# DECODER0_PVDEC_VEC_BE_HEVC register map
Vendor: Texas Instruments
Peripheral module from a debugger description file (folder J7ES).
Registers are 32-bit, read-write, reset 0x0 unless marked. A register's access mark holds for its fields unless they carry their own. Offsets are as the file gives them; lines under a group give offsets from that group; [hi:lo] are bit positions; {n}, {i} and the like mark numbered series; 'fields as' and 'values as' point back to an identical list; <NAME> marks a mode.

## DECODER0_PVDEC_VEC_BE_HEVC
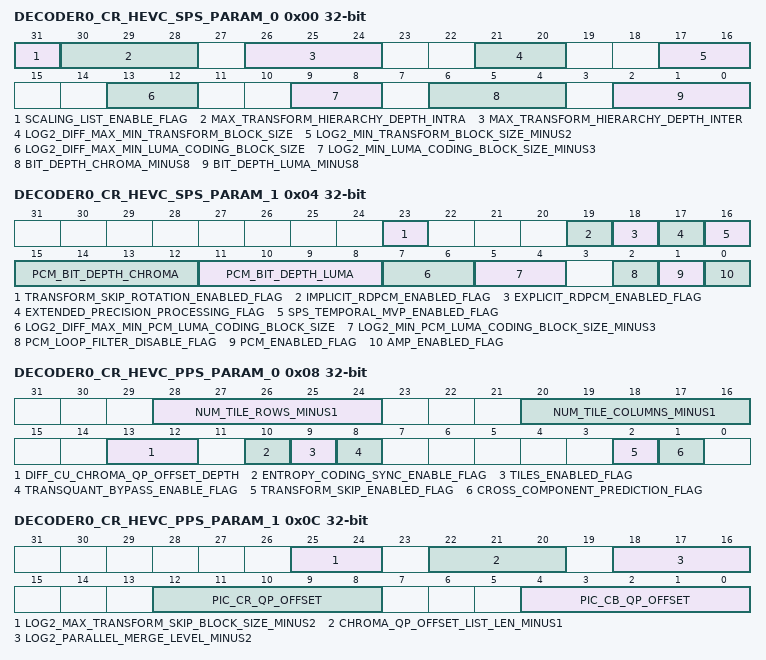
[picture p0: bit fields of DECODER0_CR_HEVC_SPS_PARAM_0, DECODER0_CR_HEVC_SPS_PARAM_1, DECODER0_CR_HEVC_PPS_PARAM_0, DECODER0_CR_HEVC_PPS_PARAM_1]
0x00 DECODER0_CR_HEVC_SPS_PARAM_0
  [31] SCALING_LIST_ENABLE_FLAG — When set to 1, the parameters set in PVDEC IQ RAM define the scaling parameters [software should program default scaling factors if explict values aren't defined in the bit stream].
  [30:28] MAX_TRANSFORM_HIERARCHY_DEPTH_INTRA — Defines the maximum hierarchy depth an Intra Coded block can be split into smaller transforms [cannot be gretaer than Log2CtbSizeY [maximum is
  [26:24] MAX_TRANSFORM_HIERARCHY_DEPTH_INTER — Defines the maximum hierarchy depth an Inter Coded block can be split into smaller transforms [cannot be gretaer than Log2CtbSizeY [maximum is
  [21:20] LOG2_DIFF_MAX_MIN_TRANSFORM_BLOCK_SIZE — Defines the difference between minimum and maximum transform block size [where LOG2_MIN_TRANSFORM_BLOCK_SIZE_MINUS2 + LOG2_DIFF_MAX_MIN_TRANSFORM_BLOCK_SIZE must be &lt;= 3, and must also be less than or equal to the maximum coded block size]
  [17:16] LOG2_MIN_TRANSFORM_BLOCK_SIZE_MINUS2 — Defines the minimum transform block size [where the minimum transform block size can not be greater than the minimum luma coded block size]
  [13:12] LOG2_DIFF_MAX_MIN_LUMA_CODING_BLOCK_SIZE — Defines the difference between minimum and maximum luma coded block size, where the resulting size is sometimes refered to as the Coded Tree Unit size or CTU_SIZE [where for Main Profile, LOG2_MIN_LUMA_CODING_BLOCK_SIZE_MINUS3 + LOG2_DIFF_MAX_MIN_LUMA_CODING_BLOCK_SIZE will be in the range 1 to 3]
  [9:8] LOG2_MIN_LUMA_CODING_BLOCK_SIZE_MINUS3 — Defines the minimum luma coded block size
  [6:4] BIT_DEPTH_CHROMA_MINUS8 — 8 less than the bit depth of chroma samples
  [2:0] BIT_DEPTH_LUMA_MINUS8 — 8 less than the bit depth of luma samples
0x04 DECODER0_CR_HEVC_SPS_PARAM_1
  [23] TRANSFORM_SKIP_ROTATION_ENABLED_FLAG — Indicates that the residual coefficients for a 4x4 Intra transform skip block should be rotated 180 degrees
  [19] IMPLICIT_RDPCM_ENABLED_FLAG — Indicates that the residual modification process for blocks using a transform bypass may be used for intra blocks
  [18] EXPLICIT_RDPCM_ENABLED_FLAG — Indicates that the residual modification process for blocks using a transform bypass may be used for inter blocks
  [17] EXTENDED_PRECISION_PROCESSING_FLAG — Indicates that an extended dynamic range is used for inter prediction interpolation and inverse transform processing
  [16] SPS_TEMPORAL_MVP_ENABLED_FLAG — If this field is set, temporal motion vector prediction may be used, so on P and B slices temporal motion vector parameters should be output in case they are required in future frames.
  [15:12] PCM_BIT_DEPTH_CHROMA — This field is 1 greater than the 'psm_sample_bit_depth_chroma_minus1' field in the bitstream, where this field can be in the range 1 to 14, but must be less than or equal to chroma sample depth
  [11:8] PCM_BIT_DEPTH_LUMA — This field is 1 greater than the 'psm_sample_bit_depth_luma_minus1' field in the bitstream, where this field can be in the range 1 to 14, but must be less than or equal to luma sample depth
  [7:6] LOG2_DIFF_MAX_MIN_PCM_LUMA_CODING_BLOCK_SIZE — If PCM is enabled, defines the difference between minimum and maximum coded block size at which PCM coding may be used [where LOG2_MIN_PCM_LUMA_CODING_BLOCK_SIZE_MINUS3 + LOG2_DIFF_MAX_MIN_PCM_LUMA_CODING_BLOCK_SIZE must be &lt;= 2]
  [5:4] LOG2_MIN_PCM_LUMA_CODING_BLOCK_SIZE_MINUS3 — If PCM is enabled, defines the minimum coded block size at which PCM coding may be used
  [2] PCM_LOOP_FILTER_DISABLE_FLAG — If PCM is enabled, this flag controls if in-loop filtering is disabled for PCM samples
  [1] PCM_ENABLED_FLAG — When set it indicates PCM coded blocks may be included in the bitstream
  [0] AMP_ENABLED_FLAG — When set it indicates PartMode of Inter prediction blocks can use asymmetric motion partitions
0x08 DECODER0_CR_HEVC_PPS_PARAM_0
  [28:24] NUM_TILE_ROWS_MINUS1 — If tiles are enabled, this field is one less than the number of tile rows the picture has been split into [where a value of zero means a tile spans the whole picture height]
  [20:16] NUM_TILE_COLUMNS_MINUS1 — If tiles are enabled, this field is one less than the number of tile columns the picture has been split into [where a value of zero means a tile spans the whole picture width]
  [13:12] DIFF_CU_CHROMA_QP_OFFSET_DEPTH — Indicates the difference between the luma coding tree block size and the minimum luma coding block size of coding units that convey cu_chroma_qp_offset_flag and cu_chroma_qp_offset_idx
  [10] ENTROPY_CODING_SYNC_ENABLE_FLAG — When set indicates CABAC state is stored after 2 CTUs in a tile row, which is then used to initialise the CABAC at the start of the next tile row
  [9] TILES_ENABLED_FLAG — When set indicates the picture is divided into tiles
  [8] TRANSQUANT_BYPASS_ENABLE_FLAG — When set indicates the cu_transquant_bypass_flag is present in the coded unit
  [2] TRANSFORM_SKIP_ENABLED_FLAG — When set indicates transform_skip_flag may be present in the residual coding syntax
  [1] CROSS_COMPONENT_PREDICTION_FLAG — Indicates that log2_res_scale_abs_plus1 and res_scale_sign_flag may be present in the transform unit syntax
0x0C DECODER0_CR_HEVC_PPS_PARAM_1
  [25:24] LOG2_MAX_TRANSFORM_SKIP_BLOCK_SIZE_MINUS2 — Indicates the maximum transform block size for which transform_skip_flag may be present [will not be larger than the largest transform block size]
  [22:20] CHROMA_QP_OFFSET_LIST_LEN_MINUS1 — Specifies 1 less than the number of cb_qp_offset_list and cr_qp_offset_list syntax elements that are present
  [18:16] LOG2_PARALLEL_MERGE_LEVEL_MINUS2 — Specifies the level at which merge/skip mode uses a single merge candidate.
  [12:8] PIC_CR_QP_OFFSET — Signed offset for QPCr relative to QPy in the range -12 to +12
  [4:0] PIC_CB_QP_OFFSET — Signed offset for QPCb relative to QPy in the range -12 to +12
0x10 DECODER0_CR_HEVC_CB_QP_OFFSET_LIST
  [29:25] PPS_CB_QP_OFFSET_LIST — List of up-to 6 sets of signed offsets for QPCb relative to QPy in the range -12 to +12 [If chroma_qp_offset_list_enabled_flag is 0, these fields should be set to 0]
0x14 DECODER0_CR_HEVC_CR_QP_OFFSET_LIST
  [29:25] PPS_CR_QP_OFFSET_LIST — List of up-to 6 sets of signed offsets for QPCr relative to QPy in the range -12 to +12 [If chroma_qp_offset_list_enabled_flag is 0, these fields should be set to 0]
0x30 DECODER0_CR_HEVC_TEMPORAL_IN_BASE_ADDRESS
  [31:6] TEMPORAL_PARAM_IN_BASE_ADDRESS — The base address of a host memory buffer which contains colocated prediction type and motion vector parameters.
0x34 DECODER0_CR_HEVC_TEMPORAL_OUT_BASE_ADDRESS
  [31:6] TEMPORAL_PARAM_OUT_BASE_ADDRESS — The base address of a host memory buffer to which prediction type and motion vector parameters are written if SPS_TEMPORAL_MVP_ENABLED_FLAG is set
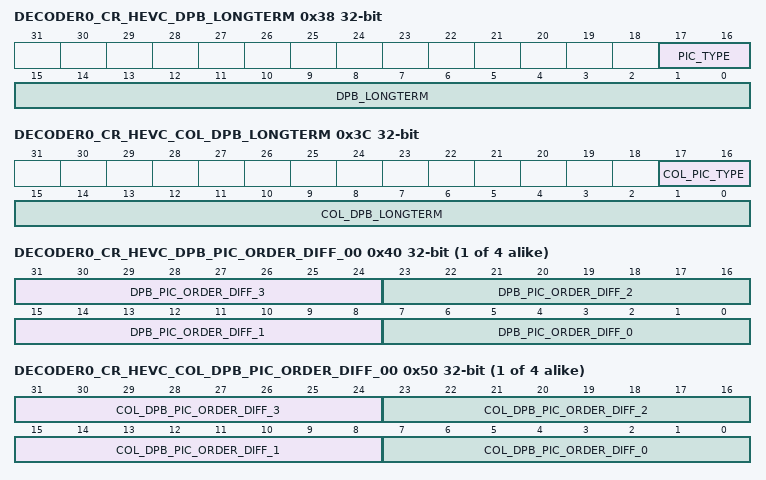
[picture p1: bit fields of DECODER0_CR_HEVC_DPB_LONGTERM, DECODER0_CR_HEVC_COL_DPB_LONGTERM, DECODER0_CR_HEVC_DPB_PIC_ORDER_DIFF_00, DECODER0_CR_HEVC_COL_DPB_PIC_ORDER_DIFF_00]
0x38 DECODER0_CR_HEVC_DPB_LONGTERM
  [17:16] PIC_TYPE — This field is from an access unit delimiter [if present].
  [15:0] DPB_LONGTERM
0x3C DECODER0_CR_HEVC_COL_DPB_LONGTERM
  [17:16] COL_PIC_TYPE — This field must be set to the same value that PIC_TYPE was set to when the collocated picture was being decoded [and must be set before the Pixel pipe decoding of a picture can start].
  [15:0] COL_DPB_LONGTERM — Essentially the same as the 'DPB_LONGTERM' field which was used when the collocated picture was the current picture,
{0x40+4i} DECODER0_CR_HEVC_DPB_PIC_ORDER_DIFF_{i:02} (i=0..3)
  [31:24] DPB_PIC_ORDER_DIFF_3 — The result of PicOrderCntVal - PicOrderCnt[DPB_Index], clipped to the range -128 to 127 [for DPB_index n*4+3] [equivalent to td or tb calculation in equation
  [23:16] DPB_PIC_ORDER_DIFF_2 — The result of PicOrderCntVal - PicOrderCnt[DPB_Index], clipped to the range -128 to 127 [for DPB_index n*4+2] [equivalent to td or tb calculation in equation
  [15:8] DPB_PIC_ORDER_DIFF_1 — The result of PicOrderCntVal - PicOrderCnt[DPB_Index], clipped to the range -128 to 127 [for DPB_index n*4+1] [equivalent to td or tb calculation in equation
  [7:0] DPB_PIC_ORDER_DIFF_0 — The result of PicOrderCntVal - PicOrderCnt[DPB_Index], clipped to the range -128 to 127 [for DPB_index n*4+0] [equivalent to td or tb calculation in equation
{0x50+4i} DECODER0_CR_HEVC_COL_DPB_PIC_ORDER_DIFF_{i:02} (i=0..3)
  [31:24] COL_DPB_PIC_ORDER_DIFF_3 — The result of PicOrderCnt[colPic] - RefPicOrderCnt[colPic, DPB_Index], clipped to the range -128 to 127 [for DPB_index n*4+3] [equivalent to td calculation in equation
  [23:16] COL_DPB_PIC_ORDER_DIFF_2 — The result of PicOrderCnt[colPic] - RefPicOrderCnt[colPic, DPB_Index], clipped to the range -128 to 127 [for DPB_index n*4+2] [equivalent to td calculation in equation
  [15:8] COL_DPB_PIC_ORDER_DIFF_1 — The result of PicOrderCnt[colPic] - RefPicOrderCnt[colPic, DPB_Index], clipped to the range -128 to 127 [for DPB_index n*4+1] [equivalent to td calculation in equation
  [7:0] COL_DPB_PIC_ORDER_DIFF_0 — The result of PicOrderCnt[colPic] - RefPicOrderCnt[colPic, DPB_Index], clipped to the range -128 to 127 [for DPB_index n*4+0] [equivalent to td calculation in equation
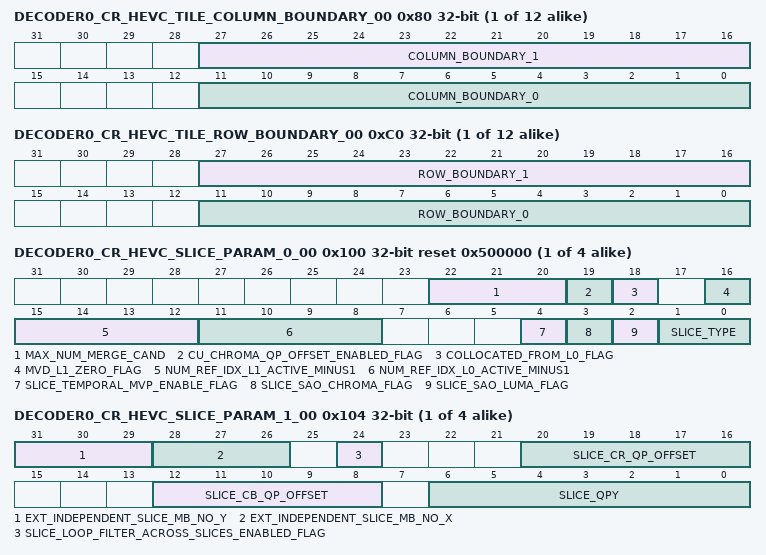
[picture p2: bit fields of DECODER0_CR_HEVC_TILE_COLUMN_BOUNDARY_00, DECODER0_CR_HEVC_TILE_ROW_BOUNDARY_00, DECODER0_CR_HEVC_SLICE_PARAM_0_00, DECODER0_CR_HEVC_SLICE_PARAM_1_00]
{0x80+4i} DECODER0_CR_HEVC_TILE_COLUMN_BOUNDARY_{i:02} (i=0..11) — If tiles are enabled and NUM_TILE_COLUMNS_MINUS1 is greater than 0, these fields define the horizontal offset in multiples of 16x16 luma blocks to the start of each tile column (used in the calculation of which neighbouring blocks are available as well as the block co-ordinate calculation). Only the first NUM_TILE_COLUMNS_MINUS1 entries are valid. The first tile always starts at offset 0, and the last tile ends at the right edge of the picture.
  [27:16] COLUMN_BOUNDARY_1 — Tile column boundary for the 3rd, 5th, ...
  [11:0] COLUMN_BOUNDARY_0 — Tile column boundary for the 2nd, 4th, ...
{0xC0+4i} DECODER0_CR_HEVC_TILE_ROW_BOUNDARY_{i:02} (i=0..11) — If tiles are enabled and NUM_TILE_ROWS_MINUS1 is greater than 0, these fields define the vertical offset in multiples of 16x16 luma blocks to the start of each tile row (used in the calculation of which neighbouring blocks are available as well as the block co-ordinate calculation). Only the first NUM_TILE_ROWS_MINUS1 entries are valid. The first tile always starts at offset 0, and the last tile ends at the bottom edge of the picture.
  [27:16] ROW_BOUNDARY_1 — Tile column boundary for the 3rd, 5th, ...
  [11:0] ROW_BOUNDARY_0 — Tile column boundary for the 2nd, 4th, ...
{0x100+0x40*i} DECODER0_CR_HEVC_SLICE_PARAM_0_{i:02} reset 0x500000 (i=0..3) — The registers in the address range 0x100 to 0x13C contain slice level parameters for a macroblock row, where four sets of slice parameter registers are supported. If the CTU size is 16x16, slice level parameters in the range 0x100 to 0x13C only apply to the top macroblock row (registers in the range 0x140 to 0x17C apply to the second macroblock row, registers in the range 0x180 to 0x1BC apply to the third macroblock row, and registers in the range 0x1C0 to 0x1FC apply to the last macroblock row). If the CTU size is 32x32, slice level parameters in the range 0x100 to 0x13C apply to the top 32 luma rows processed, and the registers in the range 0x180 to 0x1BC apply to the bottom 32 luma rows processed. If the CTU size is 64x64, slice level parameters in the range 0x100 to 0x13C apply to all 64 luma rows which are processed (and the registers in the range 0x140 to 0x1FC are not used).
  [22:20] MAX_NUM_MERGE_CAND — Calcaulated from
  [19] CU_CHROMA_QP_OFFSET_ENABLED_FLAG — Indicates that the cu_chroma_qp_offset_flag may be present in the transform unit syntax
  [18] COLLOCATED_FROM_L0_FLAG — In a B-slice, if temporal motion vector prediction is enabled, defines if collocated index is from list 0 [if set] or list 1 [if low]
  [16] MVD_L1_ZERO_FLAG — In a B slice, when set indicates the mvd_coding syntax for list 1 is not parsed, but instead is set to 0
  [15:12] NUM_REF_IDX_L1_ACTIVE_MINUS1 — In a B slice, the field is either directly from num_ref_idx_l1_active_minus1, or inferred from num_ref_idx_l1_default_active_minus1, in the range 0 to 15
  [11:8] NUM_REF_IDX_L0_ACTIVE_MINUS1 — Field is either directly from num_ref_idx_l0_active_minus1, or inferred from num_ref_idx_l0_default_active_minus1, in the range 0 to 15
  [4] SLICE_TEMPORAL_MVP_ENABLE_FLAG — When set, temporal motion vector prediction is enabled in the slice
  [3] SLICE_SAO_CHROMA_FLAG — When set, indicates SAO is enabled for the chroma component in the current slice
  [2] SLICE_SAO_LUMA_FLAG — When set, indicates SAO is enabled for the luma component in the current slice
  [1:0] SLICE_TYPE — Slice type [N.B.
{0x104+0x40*i} DECODER0_CR_HEVC_SLICE_PARAM_1_{i:02} (i=0..3)
  [31:29] EXT_INDEPENDENT_SLICE_MB_NO_Y — If picture width or height is larger than 8192 pixels, this field multiplied by 512 is added to INDEPENDENT_SLICE_MB_NO_Y to define the vertical offset of the first 16x16 block in the current independent slice, or from the start of the previous independent slice if this is a dependent slice [where this field counts from 0]
  [28:26] EXT_INDEPENDENT_SLICE_MB_NO_X — If picture width or height is larger than 8192 pixels, this field multiplied by 512 is added to INDEPENDENT_SLICE_MB_NO_Y to define the horizontal offset of the first 16x16 block in the current independent slice, or from the start of the previous independent slice if this is a dependent slice [where this field counts from 0]
  [24] SLICE_LOOP_FILTER_ACROSS_SLICES_ENABLED_FLAG — When set to 1, indicates deblocking and SAO filters may be performed across a slice boundary [when this flag is not present in the bitstream it should be set to the same value as pps_loop_filter_across_slices_enabled_flag
  [20:16] SLICE_CR_QP_OFFSET — Signed offset for QPCr relative to QPy in the range -12 to +12 [If pic_slice_chroma_qp_offsets_present_flag is 0, this field should be set to 0]
  [12:8] SLICE_CB_QP_OFFSET — Signed offset for QPCb relative to QPy in the range -12 to +12 [If pic_slice_chroma_qp_offsets_present_flag is 0, this field should be set to 0]
  [6:0] SLICE_QPY — This field stores the 'SliceQPy + QpBdOffsety' from the HEVC spec and is in the range 0 to [51+QpBdOffsety].
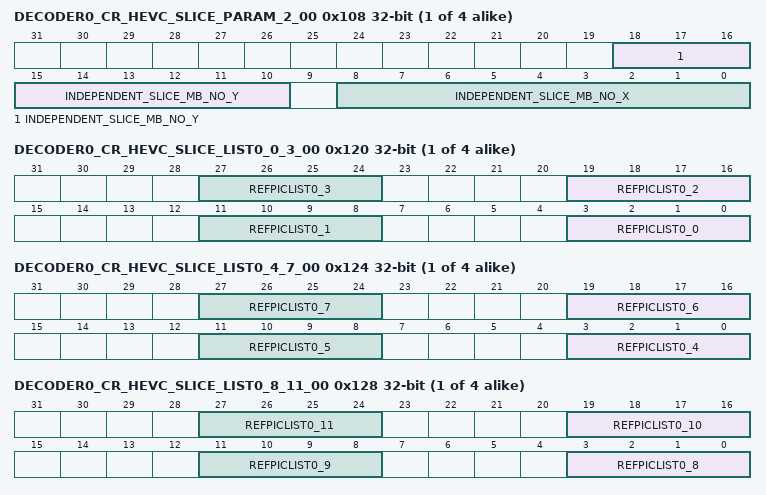
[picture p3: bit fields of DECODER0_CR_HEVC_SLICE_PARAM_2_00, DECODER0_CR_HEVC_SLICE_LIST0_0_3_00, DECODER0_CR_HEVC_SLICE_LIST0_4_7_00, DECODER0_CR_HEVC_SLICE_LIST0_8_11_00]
{0x108+0x40*i} DECODER0_CR_HEVC_SLICE_PARAM_2_{i:02} (i=0..3)
  [18:10] INDEPENDENT_SLICE_MB_NO_Y — The vertical offset of the first 16x16 block in the current independent slice, or from the start of the previous independent slice if this is a dependent slice [where this field counts from 0] [For HEVC CTU sizes larger than 16x16 this is the co-ordinate of the top left 16x16 block within the CTU] [For pictures larger than 8192 pixels high, EXT_INDEPENDENT_SLICE_MB_NO_Y is also used]
  [8:0] INDEPENDENT_SLICE_MB_NO_X — The horizontal offset of the first 16x16 block in the current independent slice, or from the start of the previous independent slice if this is a dependent slice [where this field counts from 0] [For HEVC CTU sizes larger than 16x16 this is the co-ordinate of the top left 16x16 block within the CTU]] [For pictures larger than 8192 pixels wide, EXT_INDEPENDENT_SLICE_MB_NO_X is also used]
{0x120+0x40*i} DECODER0_CR_HEVC_SLICE_LIST0_0_3_{i:02} (i=0..3) — Reference picture list 0, maps reference index to Decoded Picture Buffer (DPB) index. Can change per-slice, but the combination of both list 0 and list 1 for all slices within a picture will use a maximum of 8 Decoded Picture Buffers (multiple reference index can point to the same Decoded Picture Buffer, but may use different weighted prediction parameters).
  [8n+3:8n] REFPICLIST0_{n} (n=0..3) — DPB index of the reference picture list 0, index {n}
{0x124+0x40*i} DECODER0_CR_HEVC_SLICE_LIST0_4_7_{i:02} (i=0..3)
  [8n-29:8n-32] REFPICLIST0_{n} (n=4..7) — DPB index of the reference picture list 0, index {n}
{0x128+0x40*i} DECODER0_CR_HEVC_SLICE_LIST0_8_11_{i:02} (i=0..3)
  [8n-61:8n-64] REFPICLIST0_{n} (n=8..11) — DPB index of the reference picture list 0, index {n}
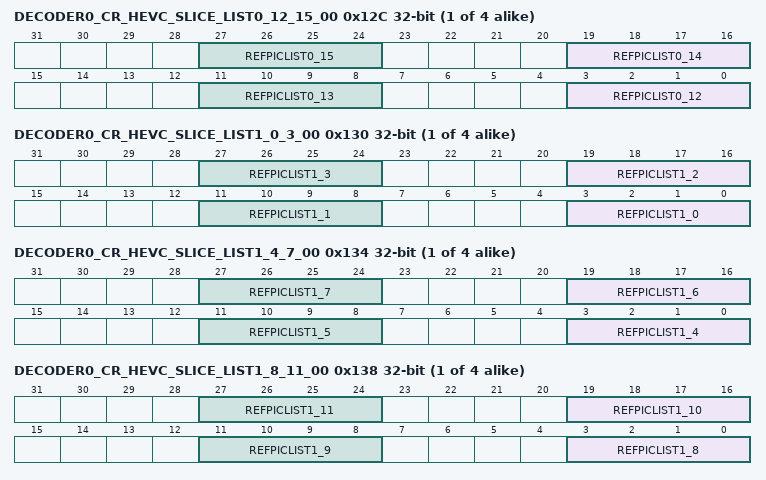
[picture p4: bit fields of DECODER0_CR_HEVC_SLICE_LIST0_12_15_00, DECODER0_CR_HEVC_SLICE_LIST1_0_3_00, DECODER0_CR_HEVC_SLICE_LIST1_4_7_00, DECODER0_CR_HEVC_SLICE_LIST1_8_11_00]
{0x12C+0x40*i} DECODER0_CR_HEVC_SLICE_LIST0_12_15_{i:02} (i=0..3)
  [8n-93:8n-96] REFPICLIST0_{n} (n=12..15) — DPB index of the reference picture list 0, index {n}
{0x130+0x40*i} DECODER0_CR_HEVC_SLICE_LIST1_0_3_{i:02} (i=0..3) — Reference picture list 1, maps reference index to Decoded Picture Buffer (DPB) index. Can change per-slice, but the combination of all slices within a picture will use a maximum of 8 Decoded Picture Buffers (multiple reference index can point to the same Decoded Picture Buffer but use a different weighted prediction parameter).
  [8n+3:8n] REFPICLIST1_{n} (n=0..3) — DPB index of the reference picture list 1, index {n}
{0x134+0x40*i} DECODER0_CR_HEVC_SLICE_LIST1_4_7_{i:02} (i=0..3)
  [8n-29:8n-32] REFPICLIST1_{n} (n=4..7) — DPB index of the reference picture list 1, index {n}
{0x138+0x40*i} DECODER0_CR_HEVC_SLICE_LIST1_8_11_{i:02} (i=0..3)
  [8n-61:8n-64] REFPICLIST1_{n} (n=8..11) — DPB index of the reference picture list 1, index {n}
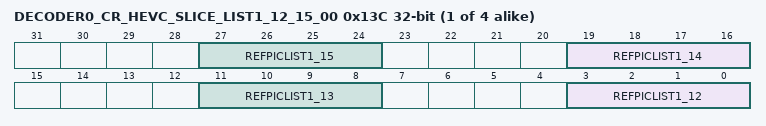
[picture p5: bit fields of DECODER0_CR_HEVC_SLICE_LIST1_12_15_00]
{0x13C+0x40*i} DECODER0_CR_HEVC_SLICE_LIST1_12_15_{i:02} (i=0..3)
  [8n-93:8n-96] REFPICLIST1_{n} (n=12..15) — DPB index of the reference picture list 1, index {n}
